# PIC32MK0128MCA028 device description
Architecture: MIPS; Family: PIC32MK; Series: PIC32MK
Registers are 32-bit, read-write, no defined reset value unless marked. A register's access mark holds for its fields unless they carry their own. Offsets are from the block's base; [hi:lo] are bit positions; {n}, {i} and the like mark numbered series.

## CTMU
Instances: CTMU 0x1f82d000 in periph_pb2_std
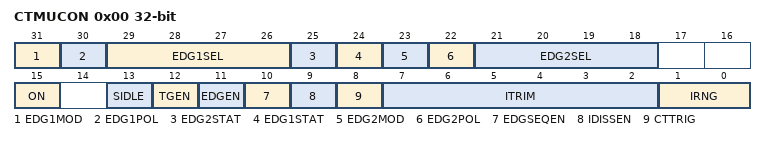
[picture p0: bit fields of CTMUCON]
0x00 CTMUCON — CTMU Control Register
  [31] EDG1MOD — Edge1 Edge Sampling Select bit
    1=Input is edge-sensitive; 0=Input is level-sensitive
  [30] EDG1POL — Edge 1 Polarity Select bit
    1=Edge1 programmed for a positive edge response; 0=Edge1 programmed for a negative edge response
  [29:26] EDG1SEL — Edge 1 Source Select bits
    15=IC4 Capture Event is selected; 14=C2OUT pin is selected; 13=C1OUT pin is selected; 12=IC3 Capture Event is selected; 11=IC2 Capture Event is selected; 10=IC1 Capture Event is selected; {v}=CTED{v-1} pin is selected (v=4..9); 3=CTED1 pin is selected; 2=CTED2 pin is selected; 1=OC1 Compare Event is selected; 0=Timer1 Event is selected
  [25] EDG2STAT — Edge2 Status bit
    1=Edge2 has occurred; 0=Edge2 has not occurred
  [24] EDG1STAT — Edge1 Status bit
    1=Edge1 has occurred; 0=Edge1 has not occurred
  [23] EDG2MOD — Edge2 Edge Sampling Select bit
    1=Input is edge-sensitive; 0=Input is level-sensitive
  [22] EDG2POL — Edge 2 Polarity Select bit
    1=Edge2 programmed for a positive edge response; 0=Edge2 programmed for a negative edge response
  [21:18] EDG2SEL — Edge 2 Source Select bits
    15=IC4 Capture Event is selected; 14=C2OUT pin is selected; 13=C1OUT pin is selected; 12=PBCLK clock is selected; 11=IC3 Capture Event is selected; 10=IC2 Capture Event is selected; 9=IC1 Capture Event is selected; {v}=CTED{v+5} pin is selected (v=4..8); 3=CTED1 pin is selected; 2=CTED2 pin is selected; 1=OC1 Compare Event is selected; 0=Timer1 Event is selected
  [15] ON — ON Enable bit
    1=Module is enabled; 0=Module is disabled
  [13] SIDLE — Stop-in-Idle-Mode
    1=Discontinue module operation when device enters Idle mode; 0=Continue module operation in Idle mode
  [12] TGEN — Time Generation Enable bit
    1=Enables edge delay generation; 0=Disables edge delay generation
  [11] EDGEN — Edge Enable bit
    1=Edges are not blocked; 0=Edges are blocked
  [10] EDGSEQEN — Edge Sequence Enable bit
    1=Edge1 must occur before Edge2 can occur; 0=No edge sequence is needed
  [9] IDISSEN — Analog Current Source Control bit
    1=Analog current source output is grounded; 0=Analog current source output is not grounded
  [8] CTTRIG — Trigger Control bit
    1=Trigger output is enabled; 0=Trigger output is disabled
  [7:2] ITRIM — Current Source Trim bits
    31=Maximum positive change from nominal current; 1=Minimum positive change from nominal current; 0=Nominal current output specified by IRNG; 63=Minimum negative change from nominal current; 33=Maximum negative change from nominal current
  [1:0] IRNG — Current Range Select bits
    3=100 times base current; 2=10 times base current; 1=Base current level; 0=1000 times base current

## DMT
Instances: DMT 0x1f800e00 in periph_pb1_std
0x00 DMTCON — Deadman Timer Control Register
  [15] ON — Deadman Timer Module Enable bit
    1=Deadman Timer module is enabled; 0=Deadman Timer module is disabled
0x10 DMTPRECLR — Deadman Timer Preclear Register
  [15:8] STEP1 — Preclear Enable bits
    64=Enables the Deadman Timer Preclear (Step 1)
0x20 DMTCLR — Deadman Timer Clear Register
  [7:0] STEP2 — Clear Timer bits
    8=Clears STEP1
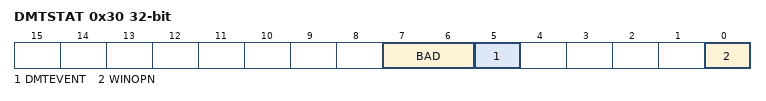
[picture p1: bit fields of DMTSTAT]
0x30 DMTSTAT ro — Deadman Timer Status Register
  [7:6] BAD — Bad STEP2 Value Detect bit
    3=Incorrect STEP1 value was detected/Incorrect STEP2 value was detected; 2=Incorrect STEP1 value was detected/Incorrect STEP2 value was not detected; 1=Incorrect STEP1 value was not detected/Incorrect STEP2 value was detected; 0=Incorrect STEP1 value was not detected/Incorrect STEP2 value was not detected
  [5] DMTEVENT — Deadman Timer Event bit
    1=Deadman timer event was detected (counter expired or bad STEP1 or STEP2 value was entered prior to counter increment); 0=Deadman timer even was not detected
  [0] WINOPN — Deadman Timer Clear Window bit
    1=Deadman timer clear window is open; 0=Deadman timer clear window is not open
0x40 DMTCNT ro — Deadman Timer Count Register
  [31:0] COUNTER
0x60 DMTPSCNT ro — Post Status Configure DMT Count Status Register
  [31:0] PSCNT
0x70 DMTPSINTV ro — Post Status Configure DMT Interval Status Register
  [31:0] PSINTV
Value list DMTSTAT__BAD1: 1=Incorrect STEP1 value was detected; 0=Incorrect STEP1 value was not detected
